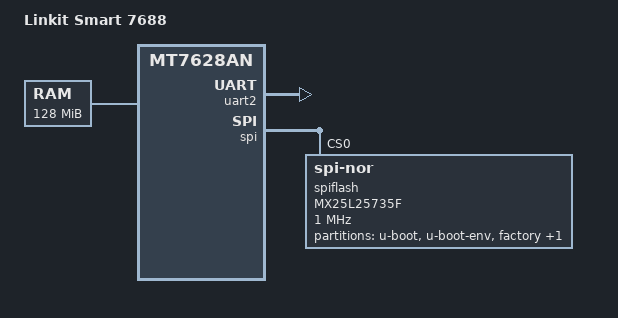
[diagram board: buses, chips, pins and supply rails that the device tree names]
#include "mt7628an.dtsi"

/ {
	model = "Linkit Smart 7688";

	memory@0 {
		device_type = "memory";
		reg = <0x00000000 0x08000000>;
	};
};

&cpupll {
	clock-frequency = <580000000>;
};

&bbppll12 {
	clock-frequency = <40000000>;
};

&uart2 {
	status = "okay";
	clock-frequency = <39628800>;
};

&spi {
	status = "okay";

	spiflash: MX25L25735F@0 {
		#address-cells = <1>;
		#size-cells = <1>;
		compatible = "jedec,spi-nor";
		spi-max-frequency = <1000000>;
		reg = <0>;

		partitions {
			compatible = "fixed-partitions";
			#address-cells = <1>;
			#size-cells = <1>;

			partition@0 {
				label = "u-boot";
				reg = <0x0 0x30000>;
			};

			partition@30000 {
				label = "u-boot-env";
				reg = <0x30000 0x10000>;
			};

			factory: partition@40000 {
				label = "factory";
				reg = <0x40000 0x10000>;
			};

			partition@50000 {
				compatible = "denx,uimage";
				label = "firmware";
				reg = <0x50000 0x1fb0000>;
			};
		};
	};
};
